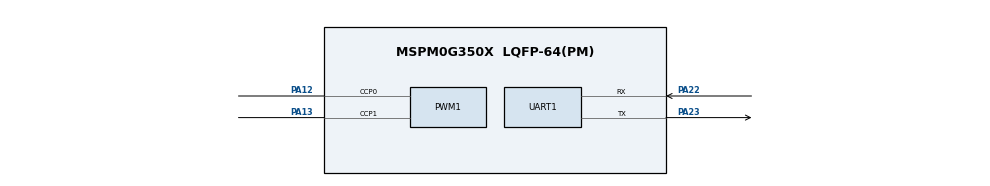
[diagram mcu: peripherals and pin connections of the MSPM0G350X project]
/**
 * @cliArgs --device "MSPM0G350X" --part "Default" --package "LQFP-64(PM)" --product "mspm0_sdk@2.11.00.07"
 * @versions {"tool":"1.26.2+4477"}
 */

/**
 * Import the modules used in this configuration.
 */
const PWM    = scripting.addModule("/ti/driverlib/PWM", {}, false);
const PWM1   = PWM.addInstance();
const SYSCTL = scripting.addModule("/ti/driverlib/SYSCTL");
const UART   = scripting.addModule("/ti/driverlib/UART", {}, false);
const UART1  = UART.addInstance();

/**
 * Write custom configuration values to the imported modules.
 */
PWM1.$name                      = "PWM_0";
PWM1.peripheral.ccp0Pin.$assign = "PA12";
PWM1.peripheral.ccp1Pin.$assign = "PA13";
PWM1.PWM_CHANNEL_0.$name        = "ti_driverlib_pwm_PWMTimerCC0";
PWM1.PWM_CHANNEL_1.$name        = "ti_driverlib_pwm_PWMTimerCC1";
PWM1.ccp0PinConfig.$name        = "ti_driverlib_gpio_GPIOPinGeneric0";
PWM1.ccp1PinConfig.$name        = "ti_driverlib_gpio_GPIOPinGeneric1";

const Board = scripting.addModule("/ti/driverlib/Board", {}, false);

SYSCTL.forceDefaultClkConfig = true;

UART1.$name             = "UART_0";
UART1.targetBaudRate    = 2400;
UART1.txPinConfig.$name = "ti_driverlib_gpio_GPIOPinGeneric2";
UART1.rxPinConfig.$name = "ti_driverlib_gpio_GPIOPinGeneric3";

/**
 * Pinmux solution for unlocked pins/peripherals. This ensures that minor changes to the automatic solver in a future
 * version of the tool will not impact the pinmux you originally saw.  These lines can be completely deleted in order to
 * re-solve from scratch.
 */
PWM1.peripheral.$suggestSolution           = "TIMG0";
Board.peripheral.$suggestSolution          = "DEBUGSS";
Board.peripheral.swclkPin.$suggestSolution = "PA20";
Board.peripheral.swdioPin.$suggestSolution = "PA19";
SYSCTL.peripheral.$suggestSolution         = "SYSCTL";
UART1.peripheral.$assign                   = "UART2";
UART1.peripheral.rxPin.$assign             = "PA22";
UART1.peripheral.txPin.$assign             = "PA23";
